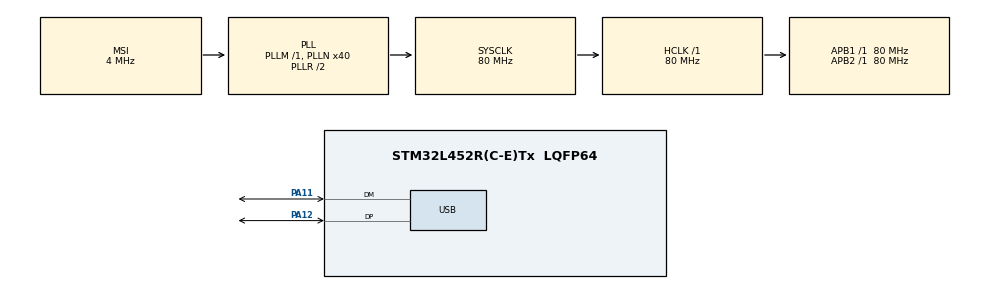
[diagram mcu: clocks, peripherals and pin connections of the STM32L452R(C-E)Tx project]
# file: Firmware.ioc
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FREERTOS.Queues01=usbRxQueue,2,HidReport_t,0,Static,usbRxQueueBuffer,usbRxQueueControlBlock;usbTxQueue,2,HidReport_t,0,Static,usbTxQueueBuffer,usbTxQueueControlBlock
FREERTOS.Tasks01=mainTask,24,256,StartMainTask,Default,NULL,Static,mainTaskBuffer,mainTaskControlBlock;taskExchange,8,256,StartTaskExchange,Default,NULL,Static,taskExchangeBuffer,taskExchangeControlBlock
Mcu.Family=STM32L4
Mcu.Name=STM32L452R(C-E)Tx
Mcu.Package=LQFP64
NVIC.PriorityGroup=NVIC_PRIORITYGROUP_4
NVIC.TIM6_DAC_IRQn=true\:0\:0\:false\:false\:true\:false\:false\:true
NVIC.TimeBase=TIM6_DAC_IRQn
NVIC.TimeBaseIP=TIM6
NVIC.USB_IRQn=true\:5\:0\:false\:false\:true\:true\:false\:true
PA11.Mode=Device
PA11.Signal=USB_DM
PA12.Mode=Device
PA12.Signal=USB_DP
PA13\ (JTMS/SWDIO).Mode=Serial_Wire
PA13\ (JTMS/SWDIO).Signal=SYS_JTMS-SWDIO
PA14\ (JTCK/SWCLK).Mode=Serial_Wire
PA14\ (JTCK/SWCLK).Signal=SYS_JTCK-SWCLK
PC14-OSC32_IN\ (PC14).Mode=LSE-External-Oscillator
PC14-OSC32_IN\ (PC14).Signal=RCC_OSC32_IN
PC15-OSC32_OUT\ (PC15).Mode=LSE-External-Oscillator
PC15-OSC32_OUT\ (PC15).Signal=RCC_OSC32_OUT
ProjectManager.HeapSize=0x200
ProjectManager.StackSize=0x400
ProjectManager.TargetToolchain=STM32CubeIDE
RCC.ADCFreq_Value=48000000
RCC.AHBFreq_Value=80000000
RCC.APB1Freq_Value=80000000
RCC.APB1TimFreq_Value=80000000
RCC.APB2Freq_Value=80000000
RCC.APB2TimFreq_Value=80000000
RCC.CortexFreq_Value=80000000
RCC.HCLKFreq_Value=80000000
RCC.HSE_VALUE=8000000
RCC.HSI48_VALUE=48000000
RCC.HSI_VALUE=16000000
RCC.MSI_VALUE=4000000
RCC.PLLN=40
RCC.PLLSAI1N=24
RCC.SYSCLKFreq_VALUE=80000000
RCC.SYSCLKSource=RCC_SYSCLKSOURCE_PLLCLK
RCC.USBFreq_Value=48000000
RCC.VCOOutputFreq_Value=160000000
RTC.Format=RTC_FORMAT_BCD
RTC.Year=20
USB.Sof_enable=ENABLE
USB_DEVICE.CLASS_NAME_FS=CUSTOM_HID
USB_DEVICE.CONFIGURATION_STRING_CUSTOMHID_FS=DCon2 HID Config
USB_DEVICE.INTERFACE_STRING_CUSTOMHID_FS=DCon2 HID Interface
USB_DEVICE.MANUFACTURER_STRING=riuson
USB_DEVICE.PID_CUSTOMHID_FS=0x5750
USB_DEVICE.PRODUCT_STRING_CUSTOMHID_FS=DCon2
USB_DEVICE.USBD_CUSTOMHID_OUTREPORT_BUF_SIZE=64
USB_DEVICE.USBD_CUSTOM_HID_REPORT_DESC_SIZE=33
USB_DEVICE.USBD_SELF_POWERED=0
USB_DEVICE.VID=0x483
USB_DEVICE.VirtualMode=CustomHid
USB_DEVICE.VirtualModeFS=Custom_Hid_FS
VP_FREERTOS_VS_CMSIS_V2.Mode=CMSIS_V2
VP_RTC_VS_RTC_Activate.Mode=RTC_Enabled
VP_RTC_VS_RTC_Calendar.Mode=RTC_Calendar
VP_SYS_VS_tim6.Mode=TIM6
VP_USB_DEVICE_VS_USB_DEVICE_CUSTOM_HID_FS.Mode=CUSTOM_HID_FS
board=custom

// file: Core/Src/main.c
/* USER CODE BEGIN Header */
/**
  ******************************************************************************
  * @file           : main.c
  * @brief          : Main program body
  ******************************************************************************
  * @attention
  *
  * <h2><center>&copy; Copyright (c) 2020 STMicroelectronics.
  * All rights reserved.</center></h2>
  *
  * This software component is licensed by ST under BSD 3-Clause license,
  * the "License"; You may not use this file except in compliance with the
  * License. You may obtain a copy of the License at:
  *                        opensource.org/licenses/BSD-3-Clause
  *
  ******************************************************************************
  */
/* USER CODE END Header */

#include "main.h"
#include "cmsis_os.h"
#include "rtc.h"
#include "usb_device.h"
#include "gpio.h"

void SystemClock_Config(void);
void MX_FREERTOS_Init(void);

int main(void)
{

  /* MCU Configuration--------------------------------------------------------*/

  /* Reset of all peripherals, Initializes the Flash interface and the Systick. */
  HAL_Init();

  /* Configure the system clock */
  SystemClock_Config();

  /* Initialize all configured peripherals */
  MX_GPIO_Init();
  MX_RTC_Init();

  /* Init scheduler */
  osKernelInitialize();  /* Call init function for freertos objects (in freertos.c) */
  MX_FREERTOS_Init();
  /* Start scheduler */
  osKernelStart();

  /* We should never get here as control is now taken by the scheduler */
  /* Infinite loop */
  while (1)
  {

  }
}

void SystemClock_Config(void)
{
  RCC_OscInitTypeDef RCC_OscInitStruct = {0};
  RCC_ClkInitTypeDef RCC_ClkInitStruct = {0};
  RCC_PeriphCLKInitTypeDef PeriphClkInit = {0};

  /** Configure LSE Drive Capability
  */
  HAL_PWR_EnableBkUpAccess();
  __HAL_RCC_LSEDRIVE_CONFIG(RCC_LSEDRIVE_LOW);
  /** Initializes the CPU, AHB and APB busses clocks
  */
  RCC_OscInitStruct.OscillatorType = RCC_OSCILLATORTYPE_LSI|RCC_OSCILLATORTYPE_LSE
                              |RCC_OSCILLATORTYPE_MSI;
  RCC_OscInitStruct.LSEState = RCC_LSE_ON;
  RCC_OscInitStruct.LSIState = RCC_LSI_ON;
  RCC_OscInitStruct.MSIState = RCC_MSI_ON;
  RCC_OscInitStruct.MSICalibrationValue = 0;
  RCC_OscInitStruct.MSIClockRange = RCC_MSIRANGE_6;
  RCC_OscInitStruct.PLL.PLLState = RCC_PLL_ON;
  RCC_OscInitStruct.PLL.PLLSource = RCC_PLLSOURCE_MSI;
  RCC_OscInitStruct.PLL.PLLM = 1;
  RCC_OscInitStruct.PLL.PLLN = 40;
  RCC_OscInitStruct.PLL.PLLP = RCC_PLLP_DIV7;
  RCC_OscInitStruct.PLL.PLLQ = RCC_PLLQ_DIV2;
  RCC_OscInitStruct.PLL.PLLR = RCC_PLLR_DIV2;
  if (HAL_RCC_OscConfig(&RCC_OscInitStruct) != HAL_OK)
  {
    Error_Handler();
  }
  /** Initializes the CPU, AHB and APB busses clocks
  */
  RCC_ClkInitStruct.ClockType = RCC_CLOCKTYPE_HCLK|RCC_CLOCKTYPE_SYSCLK
                              |RCC_CLOCKTYPE_PCLK1|RCC_CLOCKTYPE_PCLK2;
  RCC_ClkInitStruct.SYSCLKSource = RCC_SYSCLKSOURCE_PLLCLK;
  RCC_ClkInitStruct.AHBCLKDivider = RCC_SYSCLK_DIV1;
  RCC_ClkInitStruct.APB1CLKDivider = RCC_HCLK_DIV1;
  RCC_ClkInitStruct.APB2CLKDivider = RCC_HCLK_DIV1;

  if (HAL_RCC_ClockConfig(&RCC_ClkInitStruct, FLASH_LATENCY_4) != HAL_OK)
  {
    Error_Handler();
  }
  PeriphClkInit.PeriphClockSelection = RCC_PERIPHCLK_RTC|RCC_PERIPHCLK_USB;
  PeriphClkInit.RTCClockSelection = RCC_RTCCLKSOURCE_LSI;
  PeriphClkInit.UsbClockSelection = RCC_USBCLKSOURCE_PLLSAI1;
  PeriphClkInit.PLLSAI1.PLLSAI1Source = RCC_PLLSOURCE_MSI;
  PeriphClkInit.PLLSAI1.PLLSAI1M = 1;
  PeriphClkInit.PLLSAI1.PLLSAI1N = 24;
  PeriphClkInit.PLLSAI1.PLLSAI1P = RCC_PLLP_DIV7;
  PeriphClkInit.PLLSAI1.PLLSAI1Q = RCC_PLLQ_DIV2;
  PeriphClkInit.PLLSAI1.PLLSAI1R = RCC_PLLR_DIV2;
  PeriphClkInit.PLLSAI1.PLLSAI1ClockOut = RCC_PLLSAI1_48M2CLK;
  if (HAL_RCCEx_PeriphCLKConfig(&PeriphClkInit) != HAL_OK)
  {
    Error_Handler();
  }
  /** Configure the main internal regulator output voltage
  */
  if (HAL_PWREx_ControlVoltageScaling(PWR_REGULATOR_VOLTAGE_SCALE1) != HAL_OK)
  {
    Error_Handler();
  }
  /** Enable MSI Auto calibration
  */
  HAL_RCCEx_EnableMSIPLLMode();
}

 /**
  * @brief  Period elapsed callback in non blocking mode
  * @note   This function is called  when TIM6 interrupt took place, inside
  * HAL_TIM_IRQHandler(). It makes a direct call to HAL_IncTick() to increment
  * a global variable "uwTick" used as application time base.
  * @param  htim : TIM handle
  * @retval None
  */
void HAL_TIM_PeriodElapsedCallback(TIM_HandleTypeDef *htim)
{
  if (htim->Instance == TIM6) {
    HAL_IncTick();
  }
}

void Error_Handler(void)
{
}

/************************ (C) COPYRIGHT STMicroelectronics *****END OF FILE****/

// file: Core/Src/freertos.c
/* USER CODE BEGIN Header */
/**
  ******************************************************************************
  * File Name          : freertos.c
  * Description        : Code for freertos applications
  ******************************************************************************
  * @attention
  *
  * <h2><center>&copy; Copyright (c) 2020 STMicroelectronics.
  * All rights reserved.</center></h2>
  *
  * This software component is licensed by ST under Ultimate Liberty license
  * SLA0044, the "License"; You may not use this file except in compliance with
  * the License. You may obtain a copy of the License at:
  *                             www.st.com/SLA0044
  *
  ******************************************************************************
  */
/* USER CODE END Header */

#include "FreeRTOS.h"
#include "task.h"
#include "main.h"
#include "cmsis_os.h"

/* USER CODE BEGIN Includes */
#include "app_imports.h"
#include "hid_report.h"
/* USER CODE END Includes */

typedef StaticTask_t osStaticThreadDef_t;
typedef StaticQueue_t osStaticMessageQDef_t;

/* Definitions for mainTask */
osThreadId_t mainTaskHandle;
uint32_t mainTaskBuffer[ 256 ];
osStaticThreadDef_t mainTaskControlBlock;
const osThreadAttr_t mainTask_attributes = {
  .name = "mainTask",
  .stack_mem = &mainTaskBuffer[0],
  .stack_size = sizeof(mainTaskBuffer),
  .cb_mem = &mainTaskControlBlock,
  .cb_size = sizeof(mainTaskControlBlock),
  .priority = (osPriority_t) osPriorityNormal,
};
/* Definitions for taskExchange */
osThreadId_t taskExchangeHandle;
uint32_t taskExchangeBuffer[ 256 ];
osStaticThreadDef_t taskExchangeControlBlock;
const osThreadAttr_t taskExchange_attributes = {
  .name = "taskExchange",
  .stack_mem = &taskExchangeBuffer[0],
  .stack_size = sizeof(taskExchangeBuffer),
  .cb_mem = &taskExchangeControlBlock,
  .cb_size = sizeof(taskExchangeControlBlock),
  .priority = (osPriority_t) osPriorityLow,
};
/* Definitions for usbRxQueue */
osMessageQueueId_t usbRxQueueHandle;
uint8_t usbRxQueueBuffer[ 2 * sizeof( HidReport_t ) ];
osStaticMessageQDef_t usbRxQueueControlBlock;
const osMessageQueueAttr_t usbRxQueue_attributes = {
  .name = "usbRxQueue",
  .cb_mem = &usbRxQueueControlBlock,
  .cb_size = sizeof(usbRxQueueControlBlock),
  .mq_mem = &usbRxQueueBuffer,
  .mq_size = sizeof(usbRxQueueBuffer)
};
/* Definitions for usbTxQueue */
osMessageQueueId_t usbTxQueueHandle;
uint8_t usbTxQueueBuffer[ 2 * sizeof( HidReport_t ) ];
osStaticMessageQDef_t usbTxQueueControlBlock;
const osMessageQueueAttr_t usbTxQueue_attributes = {
  .name = "usbTxQueue",
  .cb_mem = &usbTxQueueControlBlock,
  .cb_size = sizeof(usbTxQueueControlBlock),
  .mq_mem = &usbTxQueueBuffer,
  .mq_size = sizeof(usbTxQueueBuffer)
};

void StartMainTask(void *argument);
void StartTaskExchange(void *argument);

extern void MX_USB_DEVICE_Init(void);
void MX_FREERTOS_Init(void); /* (MISRA C 2004 rule 8.1) */

void MX_FREERTOS_Init(void) {

  /* Create the queue(s) */
  /* creation of usbRxQueue */
  usbRxQueueHandle = osMessageQueueNew (2, sizeof(HidReport_t), &usbRxQueue_attributes);

  /* creation of usbTxQueue */
  usbTxQueueHandle = osMessageQueueNew (2, sizeof(HidReport_t), &usbTxQueue_attributes);

  /* USER CODE BEGIN RTOS_QUEUES */
  appPreInit();
  /* add queues, ... */
  /* USER CODE END RTOS_QUEUES */

  /* Create the thread(s) */
  /* creation of mainTask */
  mainTaskHandle = osThreadNew(StartMainTask, NULL, &mainTask_attributes);

  /* creation of taskExchange */
  taskExchangeHandle = osThreadNew(StartTaskExchange, NULL, &taskExchange_attributes);

}

void StartMainTask(void *argument)
{
  /* init code for USB_DEVICE */
  MX_USB_DEVICE_Init();
  /* USER CODE BEGIN StartMainTask */
  appTaskMain();
  /* USER CODE END StartMainTask */
}

void StartTaskExchange(void *argument)
{
  /* USER CODE BEGIN StartTaskExchange */
  appTaskExchange();
  /* USER CODE END StartTaskExchange */
}

/************************ (C) COPYRIGHT STMicroelectronics *****END OF FILE****/
